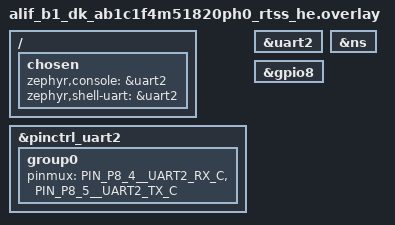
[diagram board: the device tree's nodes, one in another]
/* Copyright (C) Alif Semiconductor - All Rights Reserved.
 * Use, distribution and modification of this code is permitted under the
 * terms stated in the Alif Semiconductor Software License Agreement
 *
 * You should have received a copy of the Alif Semiconductor Software
 * License Agreement with this file. If not, please write to:
 * contact@alifsemi.com, or visit: https://alifsemi.com/license
 *
 */

/ {
	chosen {
		zephyr,console = &uart2;
		zephyr,shell-uart = &uart2;
	};
};

&pinctrl_uart2 {
	group0 {
		pinmux = <PIN_P8_4__UART2_RX_C>,
			 <PIN_P8_5__UART2_TX_C>;
	};
};

&uart2 {
	status = "okay";
};

ns: &ns {
	status = "okay";
};

gpio8: &gpio8 {
	status = "okay";
};
